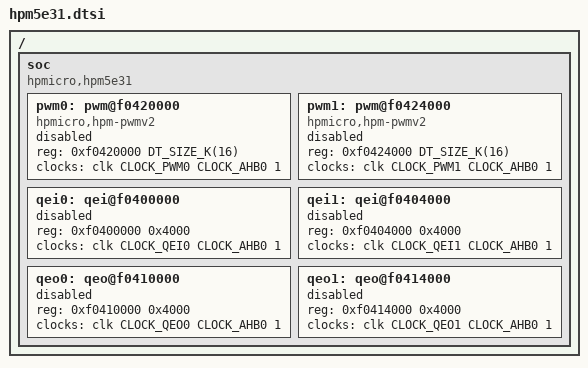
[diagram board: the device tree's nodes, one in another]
/*
* Copyright (c) 2026 HPMicro
* SPDX-License-Identifier: Apache-2.0
*/

#include <dt-bindings/clock/hpm5e31-clocks.h>
#include <hpmicro/HPM5E00/hpm5exx.dtsi>

/ {
	soc {
		compatible = "hpmicro,hpm5e31", "hpmicro,hpm5exx";
		pwm0: pwm@f0420000 {
			compatible = "hpmicro,hpm-pwmv2";
			reg = <0xf0420000 DT_SIZE_K(16)>;
			clocks = <&clk CLOCK_PWM0 CLOCK_AHB0 1>;
			status = "disabled";
			#pwm-cells = <3>;
		};

		pwm1: pwm@f0424000 {
			compatible = "hpmicro,hpm-pwmv2";
			reg = <0xf0424000 DT_SIZE_K(16)>;
			clocks = <&clk CLOCK_PWM1 CLOCK_AHB0 1>;
			status = "disabled";
			#pwm-cells = <3>;
		};

		qei0: qei@f0400000 {
			reg = <0xf0400000 0x4000>;
			clocks = <&clk CLOCK_QEI0 CLOCK_AHB0 1>;
			status = "disabled";
		};

		qei1: qei@f0404000 {
			reg = <0xf0404000 0x4000>;
			clocks = <&clk CLOCK_QEI1 CLOCK_AHB0 1>;
			status = "disabled";
		};

		qeo0: qeo@f0410000 {
			reg = <0xf0410000 0x4000>;
			clocks = <&clk CLOCK_QEO0 CLOCK_AHB0 1>;
			status = "disabled";
		};

		qeo1: qeo@f0414000 {
			reg = <0xf0414000 0x4000>;
			clocks = <&clk CLOCK_QEO1 CLOCK_AHB0 1>;
			status = "disabled";
		};
	};
};
